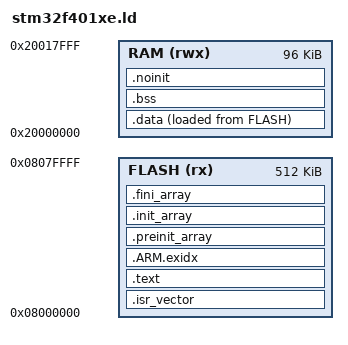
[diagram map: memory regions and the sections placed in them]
/* SPDX-License-Identifier: MIT */
/* STM32F401xE: 512 KiB flash, 96 KiB RAM */
ENTRY(Reset_Handler)

MEMORY
{
  FLASH (rx) : ORIGIN = 0x08000000, LENGTH = 512K
  RAM (rwx)  : ORIGIN = 0x20000000, LENGTH = 96K
}

_estack = ORIGIN(RAM) + LENGTH(RAM);

SECTIONS
{
  .isr_vector : { . = ALIGN(4); KEEP(*(.isr_vector)) . = ALIGN(4); } > FLASH

  .text :
  {
    . = ALIGN(4);
    *(.text) *(.text*) *(.rodata) *(.rodata*)
    KEEP(*(.init)) KEEP(*(.fini))
    . = ALIGN(4);
  } > FLASH

  .ARM.exidx : { *(.ARM.exidx* .gnu.linkonce.armexidx.*) } > FLASH

  .preinit_array : { PROVIDE_HIDDEN(__preinit_array_start = .); KEEP(*(.preinit_array*)) PROVIDE_HIDDEN(__preinit_array_end = .); } > FLASH
  .init_array : { PROVIDE_HIDDEN(__init_array_start = .); KEEP(*(SORT(.init_array.*))) KEEP(*(.init_array*)) PROVIDE_HIDDEN(__init_array_end = .); } > FLASH
  .fini_array : { PROVIDE_HIDDEN(__fini_array_start = .); KEEP(*(SORT(.fini_array.*))) KEEP(*(.fini_array*)) PROVIDE_HIDDEN(__fini_array_end = .); } > FLASH

  _sidata = LOADADDR(.data);
  .data :
  {
    . = ALIGN(4);
    _sdata = .;
    *(.data) *(.data*)
    . = ALIGN(4);
    _edata = .;
  } > RAM AT > FLASH

  .bss :
  {
    . = ALIGN(4);
    _sbss = .;
    __bss_start__ = _sbss;
    *(.bss) *(.bss*) *(COMMON)
    . = ALIGN(4);
    _ebss = .;
    __bss_end__ = _ebss;
  } > RAM

  /* Kept across a reset: the startup code does not clear it */
  .noinit (NOLOAD) : { . = ALIGN(4); *(.noinit) *(.noinit*) . = ALIGN(4); } > RAM

  . = ALIGN(8);
  PROVIDE(end = .);
  PROVIDE(_end = .);
}
